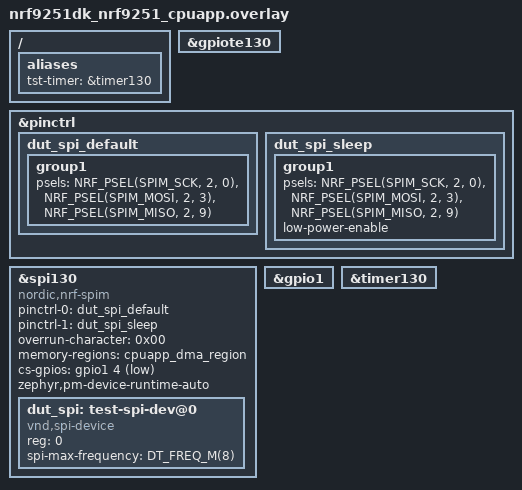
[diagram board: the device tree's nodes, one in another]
/*
 * Copyright (c) 2026 Nordic Semiconductor ASA
 *
 * SPDX-License-Identifier: LicenseRef-Nordic-5-Clause
 */

/* Required loopbacks:
 * P2.03 <-> P2.09
 */

/ {
	aliases {
		tst-timer = &timer130;
	};
};

&gpiote130 {
	status = "okay";
};

&pinctrl {
	dut_spi_default: dut_spi_default {
		group1 {
			psels = <NRF_PSEL(SPIM_SCK, 2, 0)>,
				<NRF_PSEL(SPIM_MOSI, 2, 3)>,
				<NRF_PSEL(SPIM_MISO, 2, 9)>;
		};
	};

	dut_spi_sleep: dut_spi_sleep {
		group1 {
			psels = <NRF_PSEL(SPIM_SCK, 2, 0)>,
				<NRF_PSEL(SPIM_MOSI, 2, 3)>,
				<NRF_PSEL(SPIM_MISO, 2, 9)>;
			low-power-enable;
		};
	};
};

&spi130 {
	compatible = "nordic,nrf-spim";
	status = "okay";
	pinctrl-0 = <&dut_spi_default>;
	pinctrl-1 = <&dut_spi_sleep>;
	pinctrl-names = "default", "sleep";
	overrun-character = <0x00>;
	memory-regions = <&cpuapp_dma_region>;
	cs-gpios = <&gpio1 4 GPIO_ACTIVE_LOW>;
	zephyr,pm-device-runtime-auto;

	dut_spi: test-spi-dev@0 {
		compatible = "vnd,spi-device";
		reg = <0>;
		spi-max-frequency = <DT_FREQ_M(8)>;
	};
};

&gpio1 {
	status = "okay";
};

/* Disable EXMIF node if it's added to the board definition later. */

&timer130 {
	status = "okay";
};
